# earlgrey register map
Vendor: lowRISC OpenTitan; File version: snapshot-20191101-1-518-g9293d546-dirty
CPU: RISCV 0, little endian, MPU, no FPU, 0 interrupt priority bits
Registers are 32-bit, read-write, reset 0x0 unless marked. A register's access mark holds for its fields unless they carry their own. Offsets are from the block's base; [hi:lo] are bit positions.

## uart
Base 0x40000000
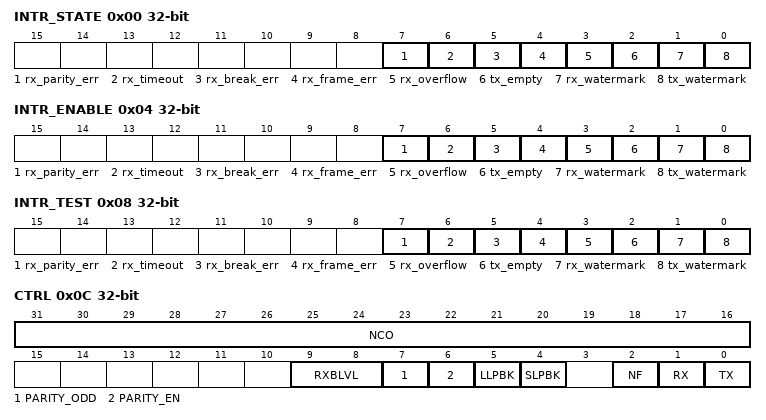
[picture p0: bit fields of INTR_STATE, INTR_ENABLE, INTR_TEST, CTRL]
0x00 INTR_STATE — Interrupt State Register
  [7] rx_parity_err write-1-clears — raised if the receiver has detected a parity error.
  [6] rx_timeout write-1-clears — raised if RX FIFO has characters remaining in the FIFO without being retrieved for the programmed time period.
  [5] rx_break_err write-1-clears — raised if break condition has been detected on receive.
  [4] rx_frame_err write-1-clears — raised if a framing error has been detected on receive.
  [3] rx_overflow write-1-clears — raised if the receive FIFO has overflowed.
  [2] tx_empty write-1-clears — raised if the transmit FIFO has emptied.
  [1] rx_watermark write-1-clears — raised if the receive FIFO is past the high-water mark.
  [0] tx_watermark write-1-clears — raised if the transmit FIFO is past the high-water mark.
0x04 INTR_ENABLE — Interrupt Enable Register
  [7] rx_parity_err — Enable interrupt when !!INTR_STATE.rx_parity_err is set
  [6] rx_timeout — Enable interrupt when !!INTR_STATE.rx_timeout is set
  [5] rx_break_err — Enable interrupt when !!INTR_STATE.rx_break_err is set
  [4] rx_frame_err — Enable interrupt when !!INTR_STATE.rx_frame_err is set
  [3] rx_overflow — Enable interrupt when !!INTR_STATE.rx_overflow is set
  [2] tx_empty — Enable interrupt when !!INTR_STATE.tx_empty is set
  [1] rx_watermark — Enable interrupt when !!INTR_STATE.rx_watermark is set
  [0] tx_watermark — Enable interrupt when !!INTR_STATE.tx_watermark is set
0x08 INTR_TEST wo — Interrupt Test Register
  [7] rx_parity_err — Write 1 to force !!INTR_STATE.rx_parity_err to 1
  [6] rx_timeout — Write 1 to force !!INTR_STATE.rx_timeout to 1
  [5] rx_break_err — Write 1 to force !!INTR_STATE.rx_break_err to 1
  [4] rx_frame_err — Write 1 to force !!INTR_STATE.rx_frame_err to 1
  [3] rx_overflow — Write 1 to force !!INTR_STATE.rx_overflow to 1
  [2] tx_empty — Write 1 to force !!INTR_STATE.tx_empty to 1
  [1] rx_watermark — Write 1 to force !!INTR_STATE.rx_watermark to 1
  [0] tx_watermark — Write 1 to force !!INTR_STATE.tx_watermark to 1
0x0C CTRL — UART control register
  [31:16] NCO — BAUD clock rate control.
  [9:8] RXBLVL — Trigger level for RX break detection. Sets the number of character times the line must be low to detect a break.
  [7] PARITY_ODD — If PARITY_EN is true, this determines the type, 1 for odd parity, 0 for even.
  [6] PARITY_EN — If true, parity is enabled in both RX and TX directions.
  [5] LLPBK — Line loopback enable. If this bit is turned on, incoming bits are forwarded to TX for testing purpose. See Block Diagram. Note that the internal design sees RX value as 1 always if line loopback is enabled.
  [4] SLPBK — System loopback enable. If this bit is turned on, any outgoing bits to TX are received through RX. See Block Diagram. Note that the TX line goes 1 if System loopback is enabled.
  [2] NF — RX noise filter enable. If the noise filter is enabled, RX line goes through the 3-tap repetition code. It ignores single IP clock period noise.
  [1] RX — RX enable
  [0] TX — TX enable
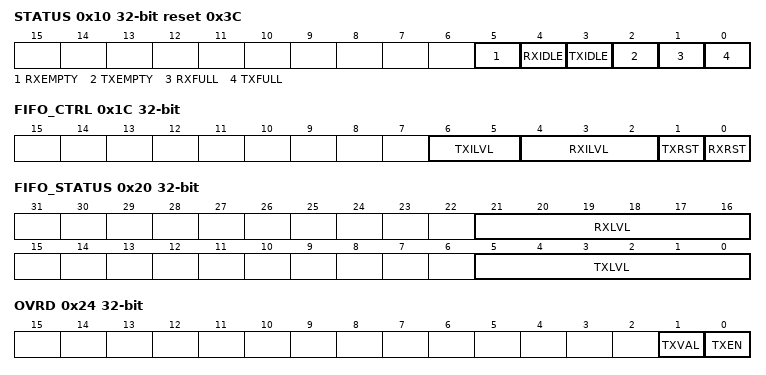
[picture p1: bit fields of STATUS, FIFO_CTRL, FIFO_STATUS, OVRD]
0x10 STATUS ro reset 0x3C — UART live status register
  [5] RXEMPTY — RX FIFO is empty
  [4] RXIDLE — RX is idle
  [3] TXIDLE — TX is idle
  [2] TXEMPTY — TX FIFO is empty
  [1] RXFULL — RX buffer is full
  [0] TXFULL — TX buffer is full
0x14 RDATA 8-bit ro — UART read data
0x18 WDATA 8-bit wo reset not defined — UART write data
0x1C FIFO_CTRL (reset mask 0x7C) — UART FIFO control register
  [6:5] TXILVL — Trigger level for TX interrupts. If the FIFO depth is greater than or equal to the setting, it raises tx_watermark interrupt.
  [4:2] RXILVL — Trigger level for RX interrupts. If the FIFO depth is greater than or equal to the setting, it raises rx_watermark interrupt.
  [1] TXRST wo — TX fifo reset. Write 1 to the register resets TX_FIFO. Read returns 0
  [0] RXRST wo — RX fifo reset. Write 1 to the register resets RX_FIFO. Read returns 0
0x20 FIFO_STATUS ro — UART FIFO status register
  [21:16] RXLVL — Current fill level of RX fifo
  [5:0] TXLVL — Current fill level of TX fifo
0x24 OVRD — TX pin override control. Gives direct SW control over TX pin state
  [1] TXVAL — Write to set the value of the TX pin
  [0] TXEN — Enable TX pin override control
0x28 VAL ro — UART oversampled values
  [15:0] RX — Last 16 oversampled values of RX. Most recent bit is bit 0, oldest 15.
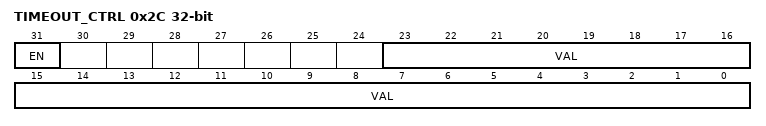
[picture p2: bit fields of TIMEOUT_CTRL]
0x2C TIMEOUT_CTRL — UART RX timeout control
  [31] EN — Enable RX timeout feature
  [23:0] VAL — RX timeout value in UART bit times
